# AVR128DA64S register map
Vendor: Atmel; File version: 1.0
CPU: other r0p0, little endian, no MPU, no FPU, 4 interrupt priority bits
Registers are 8-bit, read-write, reset 0x0 unless marked. A register's access mark holds for its fields unless they carry their own. Offsets are from the block's base; [hi:lo] are bit positions; {n}, {i} and the like mark numbered series.

## CLKCTRL — Clock controller
Base 0x00800060
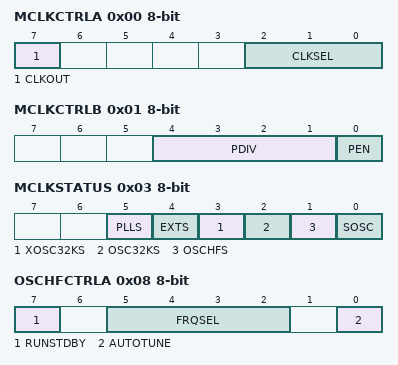
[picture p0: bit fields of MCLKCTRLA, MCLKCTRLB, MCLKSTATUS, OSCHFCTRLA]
0x00 MCLKCTRLA — MCLK Control A
  [7] CLKOUT — System clock out
  [2:0] CLKSEL — Clock select
    0=OSCHF (Internal high-frequency oscillator); 1=OSC32K (Internal 32.768 kHz oscillator); 2=XOSC32K (32.768 kHz crystal oscillator); 3=EXTCLK (External clock)
0x01 MCLKCTRLB — MCLK Control B
  [4:1] PDIV — Prescaler division
    0=2X; 1=4X; 2=8X; 3=16X; 4=32X; 5=64X; 8=6X; 9=10X; 10=12X; 11=24X; 12=48X
  [0] PEN — Prescaler enable
0x02 MCLKLOCK
  [0] LOCKEN — lock ebable
0x03 MCLKSTATUS
  [5] PLLS — PLL oscillator status
  [4] EXTS — External Clock status
  [3] XOSC32KS — 32.768 kHz Crystal Oscillator status
  [2] OSC32KS — 32KHz oscillator status
  [1] OSCHFS — High frequency oscillator status
  [0] SOSC — System Oscillator changing
0x08 OSCHFCTRLA — OSCHF Control A
  [7] RUNSTDBY — Run standby
  [5:2] FRQSEL — Frequency select
    0=1M (1 MHz system clock); 1=2M (2 MHz system clock); 2=3M (3 MHz system clock); 3=4M (4 MHz system clock (default)); 5=8M (8 MHz system clock); 6=12M (12 MHz system clock); 7=16M (16 MHz system clock); 8=20M (20 MHz system clock); 9=24M (24 MHz system clock)
  [0] AUTOTUNE
0x09 OSCHFTUNE
  [7:0] TUNE
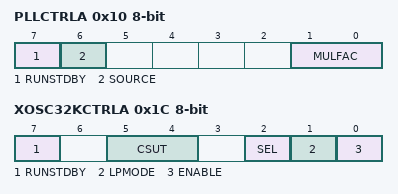
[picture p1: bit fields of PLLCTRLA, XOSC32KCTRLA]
0x10 PLLCTRLA — PLL Control A
  [7] RUNSTDBY — Run standby
  [6] SOURCE
  [1:0] MULFAC — Multiplication factor
    0=DISABLE (PLL is disabled); 1=2x (2 x multiplication factor); 2=3x (3 x multiplication factor)
0x18 OSC32KCTRLA — OSC32K Control A
  [7] RUNSTDBY — Run standby
0x1C XOSC32KCTRLA — XOSC32K Control A
  [7] RUNSTDBY — Run standby
  [5:4] CSUT — Crystal startup time
    0=1K (1k cycles); 1=16K (16k cycles); 2=32K (32k cycles); 3=64K (64k cycles)
  [2] SEL — Select
  [1] LPMODE — Low power mode
  [0] ENABLE

## CPU
Base 0x00800034
0x00 CCP — Configuration Change Protection
  [7:0] CCP — CCP signature
    157=SPM (SPM Instruction Protection); 216=IOREG (IO Register Protection)
0x07 RAMPZ — Extended Z-pointer Register
  [0] RAMPZ — Extended Z-Pointer Address bits
0x09 SP 16-bit (reset mask 0xFF) — Stack Pointer
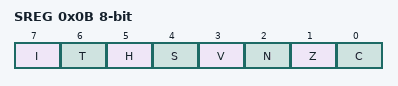
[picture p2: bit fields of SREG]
0x0B SREG — Status Register
  [7] I — Global Interrupt Enable Flag
  [6] T — Transfer Bit
  [5] H — Half Carry Flag
  [4] S — N Exclusive Or V Flag
  [3] V — Two's Complement Overflow Flag
  [2] N — Negative Flag
  [1] Z — Zero Flag
  [0] C — Carry Flag

## CPUINT — Interrupt Controller
Base 0x00800110
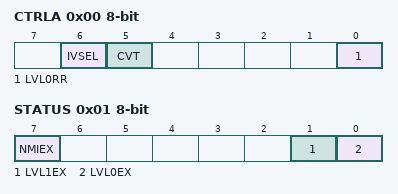
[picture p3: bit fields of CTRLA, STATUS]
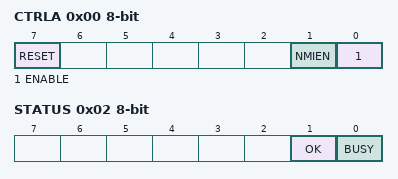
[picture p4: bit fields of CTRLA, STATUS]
0x00 CTRLA — Control A
  [6] IVSEL — Interrupt Vector Select
  [5] CVT — Compact Vector Table
  [0] LVL0RR — Round-robin Scheduling Enable
0x01 STATUS ro
  [7] NMIEX — Non-maskable Interrupt Executing
  [1] LVL1EX — Level 1 Interrupt Executing
  [0] LVL0EX — Level 0 Interrupt Executing
0x02 LVL0PRI — Interrupt Level 0 Priority
  [7:0] LVL0PRI — Interrupt Level Priority
0x03 LVL1VEC — Interrupt Level 1 Priority Vector
  [7:0] LVL1VEC — Interrupt Vector with High Priority

## CRCSCAN
Base 0x00800120
0x00 CTRLA — Control A
  [7] RESET — Reset CRC scan
  [1] NMIEN — Enable NMI Trigger
  [0] ENABLE — Enable CRC scan
0x01 CTRLB — Control B
  [1:0] SRC — CRC Source
    0=FLASH (CRC on entire flash); 1=BOOTAPP (CRC on boot and appl section of flash); 2=BOOT (CRC on boot section of flash)
0x02 STATUS ro
  [1] OK — CRC Ok
  [0] BUSY — CRC Busy

## DAC0 — Digital to Analog Converter
Base 0x008006A0
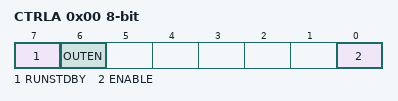
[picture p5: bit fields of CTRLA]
0x00 CTRLA — Control Register A
  [7] RUNSTDBY — Run in Standby Mode
  [6] OUTEN — Output Buffer Enable
  [0] ENABLE — DAC Enable
0x02 DATA 16-bit (reset mask 0xFF)
  [15:6] DATA

## GPR — General Purpose Registers
Base 0x0080001C
{0x0+i} GPR{i} (i=0..3) — General Purpose Register {i}

## LOCK — Lockbits
Base 0x00801040
0x00 KEY 32-bit (reset mask 0xFF) — Lock Key Bits
  [31:0] KEY — Lock Key
    0x5CC5C55C=NOLOCK (No locks); 0xA33A3AA3=RWLOCK (Read and write lock)
